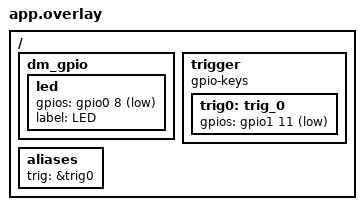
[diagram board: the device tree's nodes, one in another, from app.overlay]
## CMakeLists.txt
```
cmake_minimum_required(VERSION 3.20)

find_package(Zephyr REQUIRED HINTS $ENV{ZEPHYR_BASE})
project(nrf_iqcap)

target_sources(app PRIVATE
  src/main.c
  src/rfx.c
)

zephyr_library_include_directories(${CMAKE_CURRENT_SOURCE_DIR})
```

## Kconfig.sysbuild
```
source "${ZEPHYR_BASE}/share/sysbuild/Kconfig"

config NRF_DEFAULT_IPC_RADIO
	default y

config NETCORE_IPC_RADIO_BT_HCI_IPC
	default y
```

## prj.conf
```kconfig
# Logger module
CONFIG_LOG=y
CONFIG_LOG_MODE_IMMEDIATE=y
CONFIG_BOOT_BANNER=n
CONFIG_NCS_BOOT_BANNER=n

# USB
CONFIG_STDOUT_CONSOLE=y
CONFIG_USB_DEVICE_STACK=y
CONFIG_USB_DEVICE_PRODUCT="Zephyr CDC ACM"
CONFIG_USB_DEVICE_PID=0x0001
CONFIG_USB_DRIVER_LOG_LEVEL_ERR=y
CONFIG_USB_DEVICE_LOG_LEVEL_ERR=y

CONFIG_SERIAL=y
CONFIG_UART_INTERRUPT_DRIVEN=y
CONFIG_UART_LINE_CTRL=y
CONFIG_USB_DEVICE_INITIALIZE_AT_BOOT=n

CONFIG_ZERO_LATENCY_IRQS=y

CONFIG_NRFX_TIMER2=y
```

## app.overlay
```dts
/ {
	dm_gpio {
		led: led {
			gpios = <&gpio0 8 GPIO_ACTIVE_LOW>;
			label = "LED";
		};
	};
	trigger {
		compatible = "gpio-keys";
		trig0: trig_0 {
			gpios = <&gpio1 11 (GPIO_PULL_UP | GPIO_ACTIVE_LOW)>;
		};
	};
	aliases {
		trig = &trig0;
	};
};
```

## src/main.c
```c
#include <zephyr/types.h>
#include <zephyr/kernel.h>
#include <zephyr/logging/log.h>

#include <zephyr/usb/usb_device.h>
#include <zephyr/drivers/uart.h>
#include <zephyr/drivers/gpio.h>

#include <hal/nrf_radio.h>
#include <hal/nrf_ppi.h>
#include <hal/nrf_timer.h>
#include <hal/nrf_egu.h>

#include <nrfx_timer.h>

#include "rfx.h"

#define MAXSAMP (32*1024)
// #define MAXSAMP (512)

LOG_MODULE_REGISTER(iqcap, LOG_LEVEL_ERR);
// LOG_MODULE_REGISTER(iqcap, LOG_LEVEL_INF);

uint32_t iq_buf[MAXSAMP];

#define LED_NODE DT_ALIAS(led0)
static const struct gpio_dt_spec led = GPIO_DT_SPEC_GET(LED_NODE, gpios);

#define TRIG_NODE DT_ALIAS(trig)
static const struct gpio_dt_spec trig = GPIO_DT_SPEC_GET(TRIG_NODE, gpios);
static struct gpio_callback trig_cb_data;

const struct device *const uart_dev = DEVICE_DT_GET_ONE(zephyr_cdc_acm_uart);

static const nrfx_timer_t timer = NRFX_TIMER_INSTANCE(2);

typedef struct {
    uint32_t capture_len;
    uint32_t trigger_delay_cycles;
} config_t;

config_t config = {
    .capture_len = MAXSAMP,
    .trigger_delay_cycles = 1600,
};


static bool armed = false;

void trigger(const struct device *dev, struct gpio_callback *cb, uint32_t pins)
{
    if (!armed) {
        return;
    }

    if (config.trigger_delay_cycles == 0) {
        radio_trigger_iq_capture();
    } else {
        nrfx_timer_enable(&timer);
    }

    armed = false;
    LOG_INF("Button pressed at %" PRIu32 "\n", k_cycle_get_32());
}

static void uputchar(uint8_t c)
{
    uart_poll_out(uart_dev, c);
}

static void uart_write(const uint8_t *buf, size_t len)
{
    for (size_t i = 0; i < len; i++) {
        uputchar(buf[i]);
    }
}

static void print_wav_header()
{
    int channels = 2;
    int bits_per_sample = 16;
    int data_bytes = config.capture_len * 4;
    int file_size = 36 + data_bytes;
    int sample_rate = 16000000;
    int byte_rate = sample_rate * channels * bits_per_sample / 8;

    uputchar('R'); uputchar('I'); uputchar('F'); uputchar('F');
    uputchar(((uint8_t *)&file_size)[0]);
    uputchar(((uint8_t *)&file_size)[1]);
    uputchar(((uint8_t *)&file_size)[2]);
    uputchar(((uint8_t *)&file_size)[3]);
    uputchar('W'); uputchar('A'); uputchar('V'); uputchar('E');
    uputchar('f'); uputchar('m'); uputchar('t'); uputchar(' ');
    uputchar(16); uputchar(0); uputchar(0); uputchar(0); // Subchunk1Size
    uputchar(1); uputchar(0); // AudioFormat (PCM)
    uputchar(channels); uputchar(0); // NumChannels
    uputchar(((uint8_t *)&sample_rate)[0]);
    uputchar(((uint8_t *)&sample_rate)[1]);
    uputchar(((uint8_t *)&sample_rate)[2]);
    uputchar(((uint8_t *)&sample_rate)[3]);
    uputchar(((uint8_t *)&byte_rate)[0]);
    uputchar(((uint8_t *)&byte_rate)[1]);
    uputchar(((uint8_t *)&byte_rate)[2]);
    uputchar(((uint8_t *)&byte_rate)[3]);
    uputchar(4); uputchar(0); // BlockAlign
    uputchar(bits_per_sample); uputchar(0); // BitsPerSample
    uputchar('d'); uputchar('a'); uputchar('t'); uputchar('a');
    uputchar(((uint8_t *)&data_bytes)[0]);
    uputchar(((uint8_t *)&data_bytes)[1]);
    uputchar(((uint8_t *)&data_bytes)[2]);
    uputchar(((uint8_t *)&data_bytes)[3]);
}

void timer_event_handler(nrf_timer_event_t event_type, void *p_context)
{
    switch(event_type) {
        case NRF_TIMER_EVENT_COMPARE0:
            nrf_radio_task_trigger(NRF_RADIO, RFX_RADIO_TASK_IQCAP);
            break;
        
        default:
            break;
    }
}

static void config_timer() {

    // Count at 16 MHz (same as radio IQ capture rate)
    nrfx_timer_config_t timer_cfg = {
        .frequency = NRFX_MHZ_TO_HZ(16),
        .mode      = NRF_TIMER_MODE_TIMER,
        .bit_width = NRF_TIMER_BIT_WIDTH_32,
        .p_context = &timer,
    };
    // Uninit so we can change delay if already initialized
    nrfx_timer_uninit(&timer);
    // Initialize timer
    nrfx_timer_init(&timer, &timer_cfg, timer_event_handler);


    // Connect the nrfx irq handler which then calls our event handler
    IRQ_DIRECT_CONNECT(TIMER2_IRQn, 0, nrfx_timer_2_irq_handler, 0);
    irq_enable(TIMER2_IRQn);

    nrfx_timer_clear(&timer);
    // Use CC0 for trigger delay
    // Enable shortcut to stop and reset the timer
    nrfx_timer_extended_compare(&timer, NRF_TIMER_CC_CHANNEL0, config.trigger_delay_cycles,
            (NRF_TIMER_SHORT_COMPARE0_CLEAR_MASK | NRF_TIMER_SHORT_COMPARE0_STOP_MASK), true);
}


int main(void)
{

    const struct device *const dev = DEVICE_DT_GET(DT_CHOSEN(zephyr_console));
    uint32_t dtr = 0;

    gpio_pin_configure_dt(&led, GPIO_OUTPUT_ACTIVE);
    k_sleep(K_MSEC(300));
    gpio_pin_set_dt(&led, 0);
    k_sleep(K_MSEC(200));
    gpio_pin_set_dt(&led, 1);
    k_sleep(K_MSEC(300));
    gpio_pin_set_dt(&led, 0);
    k_sleep(K_MSEC(200));
    gpio_pin_set_dt(&led, 1);
    k_sleep(K_MSEC(300));
    gpio_pin_set_dt(&led, 0);

    // Wait for USB connection
    while (usb_enable(NULL)) { }

    for (int i = 0; !dtr && i < 100; i++) {
        uart_line_ctrl_get(dev, UART_LINE_CTRL_DTR, &dtr);
        k_sleep(K_MSEC(100));
    }

    k_sleep(K_MSEC(1000));

    LOG_INF("Console Connected!");

    init_radio(0, 2400);
    radio_set_iq_capture(&iq_buf[0], config.capture_len);

    int ret = radio_start_rx();
    k_sleep(K_MSEC(1000));
    LOG_INF("Radio started in RX mode");

    config_timer();
    LOG_INF("Timer configured");

    gpio_pin_configure_dt(&trig, GPIO_INPUT | GPIO_PULL_UP);
    gpio_pin_interrupt_configure_dt(&trig, GPIO_INT_EDGE_TO_ACTIVE);
    gpio_init_callback(&trig_cb_data, trigger, BIT(trig.pin));
    gpio_add_callback(trig.port, &trig_cb_data);
    LOG_INF("GPIO %d configured as trigger", trig.pin);

    int count = 0;

    for (;;) {
        k_sleep(K_MSEC(100));
        armed = true;
        LOG_INF("Armed for capture %d", ++count);
        gpio_pin_set_dt(&led, 1);
        
        memset(iq_buf, 0x55, sizeof(iq_buf));
        nrf_radio_event_clear(NRF_RADIO, RFX_RADIO_EVENT_IQCAPEND);
        nrf_radio_event_clear(NRF_RADIO, RFX_RADIO_EVENT_IQCAPSTART);

        if (nrf_radio_state_get(NRF_RADIO) != NRF_RADIO_STATE_RX) {
            LOG_WRN("Radio not in RX, restarting RX");
            ret = radio_start_rx();
            if (ret) {
                LOG_ERR("Failed to start RX\n");
                continue;
            }
            k_sleep(K_MSEC(100));
        }

        // Wait for capture
        while (!nrf_radio_event_check(NRF_RADIO, RFX_RADIO_EVENT_IQCAPSTART)) {
            k_sleep(K_USEC(100));
        }
        gpio_pin_set_dt(&led, 0);
        LOG_INF("IQ Capture Started");

        while (!nrf_radio_event_check(NRF_RADIO, RFX_RADIO_EVENT_IQCAPEND)) {
            k_sleep(K_USEC(100));
        }

        LOG_INF("Captured IQ samples");

        print_wav_header();
        for (int i = 0; i < config.capture_len; i++) {
            if (i % 16 == 0) {
                // Periodically yield to allow USB stack to process
                k_sleep(K_MSEC(1));
            }
            uint32_t val = iq_buf[i];
            // sign extend 12 bit samples
            int16_t i_sample = ((int)(val << 20)) / (1<<20);
            int16_t q_sample = ((int)(val << 8)) / (1<<20);

            uint8_t buf[] = {
                ((uint8_t *)&i_sample)[0], ((uint8_t *)&i_sample)[1],
                ((uint8_t *)&q_sample)[0], ((uint8_t *)&q_sample)[1],
            };

            uart_write(buf, sizeof(buf));
        }

        k_sleep(K_MSEC(1));
    }
}
```

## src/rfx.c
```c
#include "rfx.h"

#include <zephyr/types.h>
#include <zephyr/kernel.h>
#include <zephyr/logging/log.h>

#include <hal/nrf_radio.h>

LOG_MODULE_REGISTER(rfx, LOG_LEVEL_INF);

static char *str_radio_state(nrf_radio_state_t state) {
    switch (state) {
        case NRF_RADIO_STATE_DISABLED: return "DISABLED";
        case NRF_RADIO_STATE_RXRU: return "RXRU";
        case NRF_RADIO_STATE_RXIDLE: return "RXIDLE";
        case NRF_RADIO_STATE_RXDISABLE: return "RXDISABLE";
        case NRF_RADIO_STATE_RX: return "RX";
        case NRF_RADIO_STATE_TXRU: return "TXRU";
        case NRF_RADIO_STATE_TXIDLE: return "TXIDLE";
        case NRF_RADIO_STATE_TXDISABLE: return "TXDISABLE";
        case NRF_RADIO_STATE_TX: return "TX";
        default: return "UNKNOWN";
    }
}

void dump_event_status(void) {
    for (int i = 0x100; i < 0x200; i+=4) {
        if (RADIO_REG(i) != 0) {
            k_sleep(K_MSEC(1));
            LOG_DBG("EVENT 0x%03x = 0x%08x", i, RADIO_REG(i));
        }
    }
}

void init_radio(uint32_t access_addr, int frequency)
{
    LOG_DBG("Initializing radio");
    nrf_radio_power_set(NRF_RADIO, true);
    /* Set modulation and bitrate */
    nrf_radio_mode_set(NRF_RADIO, NRF_RADIO_MODE_BLE_1MBIT);

    /* Set channel */
    nrf_radio_frequency_set(NRF_RADIO, frequency);
    // IV needs to match the frequency if using packet handler at all
    nrf_radio_datawhiteiv_set(NRF_RADIO, 38);

    /* Set packet config */
    nrf_radio_packet_conf_t pkt_conf = {
        .lflen = 6UL, // Length field length in bits
        .s0len = 1UL,
        .s1len = 2UL,
        .s1incl = false,
        .plen = NRF_RADIO_PREAMBLE_LENGTH_8BIT,
        .crcinc = false, // CRC included in length field
        .statlen = 0UL,
        .balen = 3UL,
        .big_endian = false,
        .maxlen = 0, // Max payload length
        .whiteen = true            // Packet whitening
    };
    nrf_radio_packet_configure(NRF_RADIO, &pkt_conf);

    /* Address */
    nrf_radio_base0_set(NRF_RADIO, access_addr << 8);
    nrf_radio_prefix0_set(NRF_RADIO, access_addr >> 24);
    nrf_radio_txaddress_set(NRF_RADIO, 0); // Transmit using logical address 0 (base0 and prefix0)
    
    if (access_addr) {
        nrf_radio_rxaddresses_set(NRF_RADIO, 1<<0); // Enable RX of logical address 0
    } else {
        nrf_radio_rxaddresses_set(NRF_RADIO, 0); // Disable RX
    }

    /* CRC Config */
    nrf_radio_crc_configure(NRF_RADIO,
                            3,
                            NRF_RADIO_CRC_ADDR_SKIP,
                            0x00065B);
	nrf_radio_crcinit_set(NRF_RADIO, 0x55555555);

    /* Shortcuts */
    // Ready -> Start shortcut
    nrf_radio_shorts_set(NRF_RADIO, NRF_RADIO_SHORT_READY_START_MASK);
}

int radio_set_bcc(int bitcount) {
    if (bitcount < 0 || bitcount > 255) {
        return -EINVAL;
    }
    
    NRF_RADIO->BCC = bitcount;

    nrf_radio_shorts_enable(NRF_RADIO, NRF_RADIO_SHORT_ADDRESS_BCSTART_MASK);
    return 0;
}

int radio_disable_bcc(void) {
    nrf_radio_shorts_disable(NRF_RADIO, NRF_RADIO_SHORT_ADDRESS_BCSTART_MASK);
    return 0;
}

int radio_set_iq_capture(uint32_t *data, size_t nsamp) {

    if (!data) {
        RADIO_REG(PHDMASEL) = RFX_RADIO_PHDMA_PKT;
        RADIO_REG(IQCONF) = RFX_RADIO_IQCAP_DIS;
        return 0;
    }

    RADIO_REG(IQCONF) = RFX_RADIO_IQCAP_DIS;

    // Never gets set?
    RADIO_REG(REG_A40) = 0; // Clear A40

    // Set the IQ capture pointer and length
    RADIO_REG(REG_IQPTR) = (uint32_t)data;
    RADIO_REG(REG_IQLEN) = nsamp;

    // Without A30 bit 0 set, IQ capture does not start
    // Without A44 bit 0 set, capture gets 0 samples but packet handler works
    RADIO_REG(PHDMASEL) = RFX_RADIO_PHDMA_IQ;
    RADIO_REG(IQCONF) = RFX_RADIO_IQCAP_EN;

    return 0;
}

int radio_trigger_iq_capture(void) {
    nrf_radio_task_trigger(NRF_RADIO, RFX_RADIO_TASK_IQCAP);
    return 0;
}

int radio_start_rx(void) {

    LOG_DBG("Starting RX");

    // We want to be in DISABLED
    // RXIDLE is configured to shortcut to RX
    bool is_disabled = false;
    while (!is_disabled) {
        nrf_radio_state_t state = nrf_radio_state_get(NRF_RADIO);
        LOG_DBG("Radio state: %s", str_radio_state(state));
        switch (state) {
            case NRF_RADIO_STATE_RX:
            case NRF_RADIO_STATE_TX:
                /* Stop TX/RX, return to TXIDLE/RXIDLE */
                nrf_radio_task_trigger(NRF_RADIO, NRF_RADIO_TASK_STOP);
                break;
            case NRF_RADIO_STATE_TXIDLE:
            case NRF_RADIO_STATE_RXIDLE:
                /* Need to go to DISABLE */
                nrf_radio_task_trigger(NRF_RADIO, NRF_RADIO_TASK_DISABLE);
                break;
            case NRF_RADIO_STATE_DISABLED:
                is_disabled = true;
                break;
            case NRF_RADIO_STATE_RXDISABLE:
            case NRF_RADIO_STATE_TXDISABLE:
                /* Keep waiting until we're in DISABLED */
                break;
            default:
                /* Radio in incompatible state. Give up */
                LOG_ERR("RX Failed, incompatible state. State: %s", str_radio_state(state));
                return -EIO;
        }
    }

    NRF_RADIO->PCNF1 = (NRF_RADIO->PCNF1 & ~RADIO_PCNF1_MAXLEN_Msk);

    // Clear the event flags
    nrf_radio_event_clear(NRF_RADIO, RFX_RADIO_EVENT_IQCAPEND);
    nrf_radio_event_clear(NRF_RADIO, RFX_RADIO_EVENT_IQCAPSTART);

    // Enter the RX state and begin listening (will shortcut from RXIDLE to RX)
	LOG_DBG("Listening");
    nrf_radio_task_trigger(NRF_RADIO, NRF_RADIO_TASK_RXEN);

    return 0;
}
```

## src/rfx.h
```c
/**
 * @file rfx.h
 * @brief Extended RF-related functionality
 *
 */

#ifndef RFX_H__
#define RFX_H__

#ifdef __cplusplus
extern "C" {
#endif

#include <zephyr/types.h>
#include <hal/nrf_radio.h>

#define TASKS_IQCAP         (0x060)
#define EVENTS_IQCAPEND     (0x160)
#define EVENTS_IQCAPSTART   (0x164)
#define IQCONF              (0xa30)
#define REG_IQPTR           (0xa34)
#define REG_IQLEN           (0xa38)
#define REG_IQAMOUNT        (0xa3c)
#define REG_A40             (0xa40)
#define PHDMASEL            (0xa44)

#define RFX_RADIO_IQCAP_EN  (1 << 0)
#define RFX_RADIO_IQCAP_DIS (0 << 0)

#define RFX_RADIO_PHDMA_PKT (0 << 0)
#define RFX_RADIO_PHDMA_IQ  (1 << 0)


#define RFX_RADIO_TASK_IQCAP            (TASKS_IQCAP)
#define RFX_RADIO_EVENT_IQCAPEND        (EVENTS_IQCAPEND)
#define RFX_RADIO_EVENT_IQCAPSTART      (EVENTS_IQCAPSTART)


#define RADIO_REG(x) (((volatile uint32_t *)NRF_RADIO)[x >> 2])

#define BLE_LENGTH_OFFSET   1
#define BLE_PAYLOAD_OFFSET  3

/**
 * @brief Initialize BLE radio
 * @param access_addr The 32-bit access address to use (0x8e89bed6 for BLE advertisements)
 * @param frequency The frequency in MHz to set (note the radio is internally offset tuned)
 */
void init_radio(uint32_t access_addr, int frequency);

/**
 * @brief Configure bit counter event for packet reception
 * 
 * @param bitcount Number of bits to trigger after (0-255)
 * @return 0 on success
 *       - -EINVAL: Invalid bitcount value
 */
int radio_set_bcc(int bitcount);

/**
 * @brief Disable bit counter event
 * 
 * @return 0 on success
 */
int radio_disable_bcc(void);

/**
 * @brief Start IQ sample capture
 * 
 * @return 0 on success, negative error code on failure
 */
int radio_trigger_iq_capture(void);

/**
 * @brief Configure IQ sample capture during packet reception
 * 
 * If `data` is NULL, IQ capture is disabled.
 * 
 * @param data Pointer to buffer to store IQ samples
 * @param nsamp Number of IQ samples to capture
 * @return 0 on success, negative error code on failure
 */
int radio_set_iq_capture(uint32_t *data, size_t nsamp);

/**
 * @brief Start radio in RX mode
 * 
 * @return 0 on success, negative error code on failure
 */
int radio_start_rx(void);

#ifdef __cplusplus
}
#endif

 #endif // RFX_H__
```
